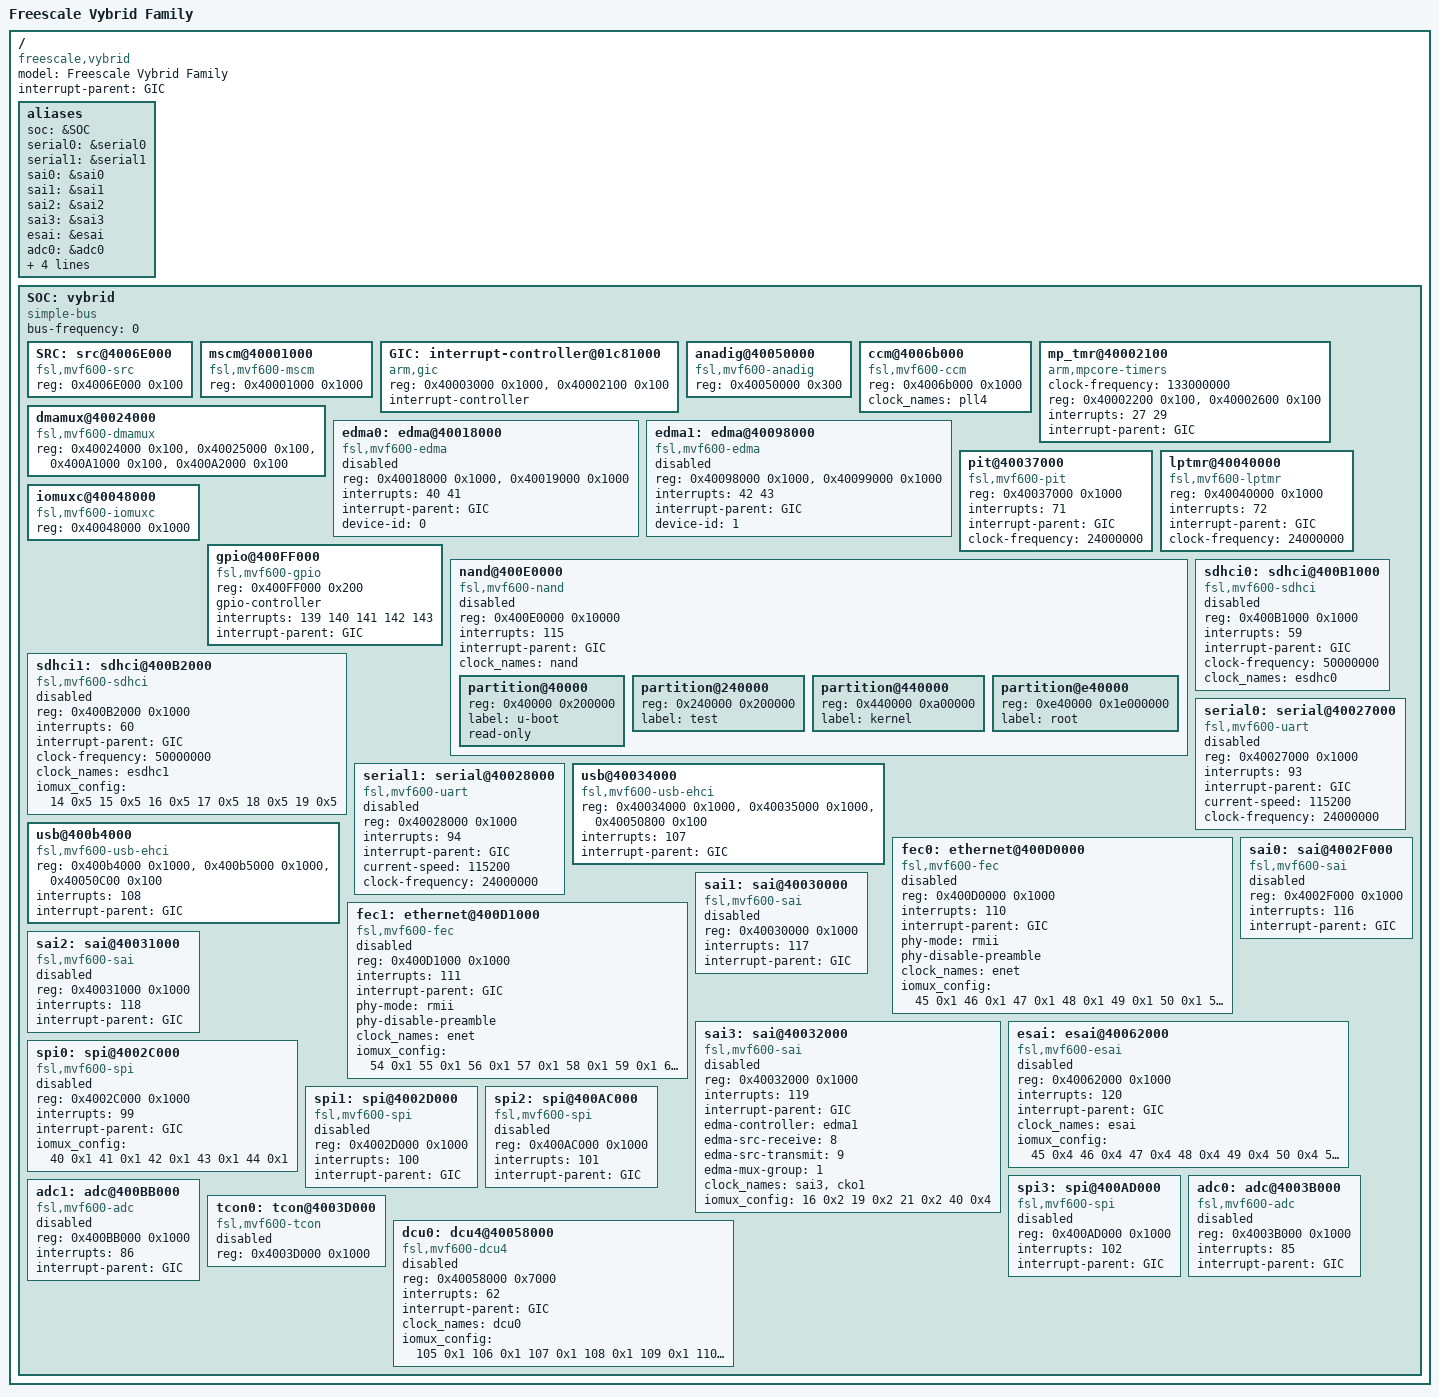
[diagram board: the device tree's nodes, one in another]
/*-
 * Copyright (c) 2013-2014 Ruslan Bukin <br@bsdpad.com>
 * All rights reserved.
 *
 * Redistribution and use in source and binary forms, with or without
 * modification, are permitted provided that the following conditions
 * are met:
 * 1. Redistributions of source code must retain the above copyright
 *    notice, this list of conditions and the following disclaimer.
 * 2. Redistributions in binary form must reproduce the above copyright
 *    notice, this list of conditions and the following disclaimer in the
 *    documentation and/or other materials provided with the distribution.
 *
 * THIS SOFTWARE IS PROVIDED BY THE AUTHOR AND CONTRIBUTORS ``AS IS'' AND
 * ANY EXPRESS OR IMPLIED WARRANTIES, INCLUDING, BUT NOT LIMITED TO, THE
 * IMPLIED WARRANTIES OF MERCHANTABILITY AND FITNESS FOR A PARTICULAR PURPOSE
 * ARE DISCLAIMED. IN NO EVENT SHALL THE AUTHOR OR CONTRIBUTORS BE LIABLE
 * FOR ANY DIRECT, INDIRECT, INCIDENTAL, SPECIAL, EXEMPLARY, OR CONSEQUENTIAL
 * DAMAGES (INCLUDING, BUT NOT LIMITED TO, PROCUREMENT OF SUBSTITUTE GOODS
 * OR SERVICES; LOSS OF USE, DATA, OR PROFITS; OR BUSINESS INTERRUPTION)
 * HOWEVER CAUSED AND ON ANY THEORY OF LIABILITY, WHETHER IN CONTRACT, STRICT
 * LIABILITY, OR TORT (INCLUDING NEGLIGENCE OR OTHERWISE) ARISING IN ANY WAY
 * OUT OF THE USE OF THIS SOFTWARE, EVEN IF ADVISED OF THE POSSIBILITY OF
 * SUCH DAMAGE.
 *
 * $FreeBSD$
 */

/ {
	model = "Freescale Vybrid Family";
	compatible = "freescale,vybrid", "fsl,mvf";
	#address-cells = <1>;
	#size-cells = <1>;

	interrupt-parent = <&GIC>;

	aliases {
		soc = &SOC;
		serial0 = &serial0;
		serial1 = &serial1;
		sai0 = &sai0;
		sai1 = &sai1;
		sai2 = &sai2;
		sai3 = &sai3;
		esai = &esai;
		adc0 = &adc0;
		adc1 = &adc1;
		edma0 = &edma0;
		edma1 = &edma1;
		src = &SRC;
	};

	SOC: vybrid {
		#address-cells = <1>;
		#size-cells = <1>;
		compatible = "simple-bus";
		ranges;
		bus-frequency = <0>;

		SRC: src@4006E000 {
			compatible = "fsl,mvf600-src";
			reg = <0x4006E000 0x100>;
		};

		mscm@40001000 {
			compatible = "fsl,mvf600-mscm";
			reg = <0x40001000 0x1000>;
		};

		GIC: interrupt-controller@01c81000 {
			compatible = "arm,gic";
			reg = 	<0x40003000 0x1000>,	/* Distributor Registers */
				<0x40002100 0x100>;	/* CPU Interface Registers */
			interrupt-controller;
			#interrupt-cells = <1>;
		};

		anadig@40050000 {
			compatible = "fsl,mvf600-anadig";
			reg = <0x40050000 0x300>;
		};

		ccm@4006b000 {
			compatible = "fsl,mvf600-ccm";
			reg = <0x4006b000 0x1000>;
			clock_names = "pll4";
		};

		mp_tmr@40002100 {
			compatible = "arm,mpcore-timers";
			clock-frequency = <133000000>;
			#address-cells = <1>;
			#size-cells = <0>;
			reg = < 0x40002200 0x100 >, /* Global Timer Registers */
			      < 0x40002600 0x100 >; /* Private Timer Registers */
			interrupts = < 27 29 >;
			interrupt-parent = < &GIC >;
		};

		dmamux@40024000 {
			compatible = "fsl,mvf600-dmamux";
			reg = <0x40024000 0x100>,
			      <0x40025000 0x100>,
			      <0x400A1000 0x100>,
			      <0x400A2000 0x100>;
		};

		edma0: edma@40018000 {
			compatible = "fsl,mvf600-edma";
			reg = <0x40018000 0x1000>,
			      <0x40019000 0x1000>; /* TCD */
			interrupts = < 40 41 >;
			interrupt-parent = <&GIC>;
			device-id = < 0 >;
			status = "disabled";
		};

		edma1: edma@40098000 {
			compatible = "fsl,mvf600-edma";
			reg = <0x40098000 0x1000>,
			      <0x40099000 0x1000>; /* TCD */
			interrupts = < 42 43 >;
			interrupt-parent = <&GIC>;
			device-id = < 1 >;
			status = "disabled";
		};

		pit@40037000 {
			compatible = "fsl,mvf600-pit";
			reg = <0x40037000 0x1000>;
			interrupts = < 71 >;
			interrupt-parent = <&GIC>;
			clock-frequency = < 24000000 >;
		};

		lptmr@40040000 {
			compatible = "fsl,mvf600-lptmr";
			reg = <0x40040000 0x1000>;
			interrupts = < 72 >;
			interrupt-parent = <&GIC>;
			clock-frequency = < 24000000 >;
		};

		iomuxc@40048000 {
			compatible = "fsl,mvf600-iomuxc";
			reg = <0x40048000 0x1000>;
		};

		gpio@400FF000 {
			compatible = "fsl,mvf600-gpio";
			reg = <0x400FF000 0x200>;
			#gpio-cells = <3>;
			gpio-controller;
			interrupts = < 139 140 141 142 143 >;
			interrupt-parent = <&GIC>;
		};

		nand@400E0000 {
			#address-cells = <1>;
			#size-cells = <1>;
			compatible = "fsl,mvf600-nand";
			reg = <0x400E0000 0x10000>;
			interrupts = < 115 >;
			interrupt-parent = <&GIC>;
			clock_names = "nand";
			status = "disabled";

			partition@40000 {
				reg = <0x40000 0x200000>; /* 2MB */
				label =	"u-boot";
				read-only;
			};

			partition@240000 {
				reg = <0x240000 0x200000>; /* 2MB */
				label =	"test";
			};

			partition@440000 {
				reg = <0x440000 0xa00000>; /* 10MB */
				label =	"kernel";
			};

			partition@e40000 {
				reg = <0xe40000 0x1e000000>; /* 480MB */
				label =	"root";
			};
		};

		sdhci0: sdhci@400B1000 {
			compatible = "fsl,mvf600-sdhci";
			reg = <0x400B1000 0x1000>;
			interrupts = < 59 >;
			interrupt-parent = <&GIC>;
			clock-frequency = <50000000>;
			status = "disabled";
			clock_names = "esdhc0";
		};

		sdhci1: sdhci@400B2000 {
			compatible = "fsl,mvf600-sdhci";
			reg = <0x400B2000 0x1000>;
			interrupts = < 60 >;
			interrupt-parent = <&GIC>;
			clock-frequency = <50000000>;
			status = "disabled";
			clock_names = "esdhc1";
			iomux_config = < 14 0x5 15 0x5
					 16 0x5 17 0x5
					 18 0x5 19 0x5 >;
		};

		serial0: serial@40027000 {
			compatible = "fsl,mvf600-uart";
			reg = <0x40027000 0x1000>;
			interrupts = <93>;
			interrupt-parent = <&GIC>;
			current-speed = <115200>;
			clock-frequency = < 24000000 >;
			status = "disabled";
		};

		serial1: serial@40028000 {
			compatible = "fsl,mvf600-uart";
			reg = <0x40028000 0x1000>;
			interrupts = <94>;
			interrupt-parent = <&GIC>;
			current-speed = <115200>;
			clock-frequency = < 24000000 >;
			status = "disabled";
		};

		usb@40034000 {
			compatible = "fsl,mvf600-usb-ehci", "usb-ehci";
			reg = < 0x40034000 0x1000 >, /* ehci */
			      < 0x40035000 0x1000 >, /* usbc */
			      < 0x40050800 0x100 >; /* phy */
			interrupts = < 107 >;
			interrupt-parent = <&GIC>;
		};

		usb@400b4000 {
			compatible = "fsl,mvf600-usb-ehci", "usb-ehci";
			reg = < 0x400b4000 0x1000 >, /* ehci */
			      < 0x400b5000 0x1000 >, /* usbc */
			      < 0x40050C00 0x100 >; /* phy */
			interrupts = < 108 >;
			interrupt-parent = <&GIC>;
		};

		fec0: ethernet@400D0000 {
			compatible = "fsl,mvf600-fec";
			reg = <0x400D0000 0x1000>;
			interrupts = < 110 >;
			interrupt-parent = <&GIC>;
			phy-mode = "rmii";
			phy-disable-preamble;
			status = "disabled";
			clock_names = "enet";
			iomux_config = < 45 0x1 46 0x1
					 47 0x1 48 0x1
					 49 0x1 50 0x1
					 51 0x1 52 0x1
					 53 0x1 >;
		};

		fec1: ethernet@400D1000 {
			compatible = "fsl,mvf600-fec";
			reg = <0x400D1000 0x1000>;
			interrupts = < 111 >;
			interrupt-parent = <&GIC>;
			phy-mode = "rmii";
			phy-disable-preamble;
			status = "disabled";
			clock_names = "enet";
			iomux_config = < 54 0x1 55 0x1
					 56 0x1 57 0x1
					 58 0x1 59 0x1
					 60 0x1 61 0x1
					 62 0x1 >;
		};

		sai0: sai@4002F000 {
			compatible = "fsl,mvf600-sai";
			reg = <0x4002F000 0x1000>;
			interrupts = < 116 >;
			interrupt-parent = <&GIC>;
			status = "disabled";
		};

		sai1: sai@40030000 {
			compatible = "fsl,mvf600-sai";
			reg = <0x40030000 0x1000>;
			interrupts = < 117 >;
			interrupt-parent = <&GIC>;
			status = "disabled";
		};

		sai2: sai@40031000 {
			compatible = "fsl,mvf600-sai";
			reg = <0x40031000 0x1000>;
			interrupts = < 118 >;
			interrupt-parent = <&GIC>;
			status = "disabled";
		};

		sai3: sai@40032000 {
			compatible = "fsl,mvf600-sai";
			reg = <0x40032000 0x1000>;
			interrupts = < 119 >;
			interrupt-parent = <&GIC>;
			status = "disabled";
			edma-controller = <&edma1>;
			edma-src-receive = < 8 >;
			edma-src-transmit = < 9 >;
			edma-mux-group = < 1 >;
			clock_names = "sai3", "cko1";
			iomux_config = < 16 0x2
					 19 0x2
					 21 0x2
					 40 0x4 >; /* CKO1 */
		};

		esai: esai@40062000 {
			compatible = "fsl,mvf600-esai";
			reg = <0x40062000 0x1000>;
			interrupts = < 120 >;
			interrupt-parent = <&GIC>;
			status = "disabled";
			clock_names = "esai";
			iomux_config = < 45 0x4 46 0x4
					 47 0x4 48 0x4
					 49 0x4 50 0x4
					 51 0x4 52 0x4
					 78 0x3 40 0x4>;
		};

		spi0: spi@4002C000 {
			compatible = "fsl,mvf600-spi";
			reg = <0x4002C000 0x1000>;
			interrupts = < 99 >;
			interrupt-parent = <&GIC>;
			status = "disabled";
			iomux_config = < 40 0x1 41 0x1
					 42 0x1 43 0x1
					 44 0x1 >;
		};

		spi1: spi@4002D000 {
			compatible = "fsl,mvf600-spi";
			reg = <0x4002D000 0x1000>;
			interrupts = < 100 >;
			interrupt-parent = <&GIC>;
			status = "disabled";
		};

		spi2: spi@400AC000 {
			compatible = "fsl,mvf600-spi";
			reg = <0x400AC000 0x1000>;
			interrupts = < 101 >;
			interrupt-parent = <&GIC>;
			status = "disabled";
		};

		spi3: spi@400AD000 {
			compatible = "fsl,mvf600-spi";
			reg = <0x400AD000 0x1000>;
			interrupts = < 102 >;
			interrupt-parent = <&GIC>;
			status = "disabled";
		};

		adc0: adc@4003B000 {
			compatible = "fsl,mvf600-adc";
			reg = <0x4003B000 0x1000>;
			interrupts = < 85 >;
			interrupt-parent = <&GIC>;
			status = "disabled";
		};

		adc1: adc@400BB000 {
			compatible = "fsl,mvf600-adc";
			reg = <0x400BB000 0x1000>;
			interrupts = < 86 >;
			interrupt-parent = <&GIC>;
			status = "disabled";
		};

		tcon0: tcon@4003D000 {
			compatible = "fsl,mvf600-tcon";
			reg = <0x4003D000 0x1000>;
			status = "disabled";
		};

		dcu0: dcu4@40058000 {
			compatible = "fsl,mvf600-dcu4";
			reg = <0x40058000 0x7000>;
			interrupts = < 62 >;
			interrupt-parent = <&GIC>;
			status = "disabled";
			clock_names = "dcu0";
			iomux_config = < 105 0x1 106 0x1
					 107 0x1 108 0x1
					 109 0x1 110 0x1
					 111 0x1 112 0x1
					 113 0x1 114 0x1
					 115 0x1 116 0x1
					 117 0x1 118 0x1
					 119 0x1 120 0x1
					 121 0x1 122 0x1
					 123 0x1 124 0x1
					 125 0x1 126 0x1
					 127 0x1 128 0x1
					 129 0x1 130 0x1
					 131 0x1 132 0x1
					 133 0x1 >;
		};
	};
};
